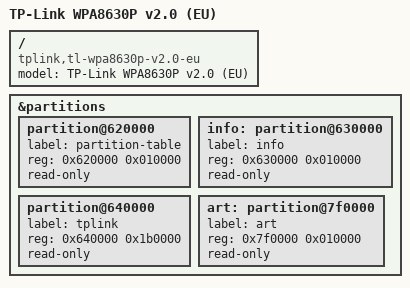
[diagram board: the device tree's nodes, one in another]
// SPDX-License-Identifier: GPL-2.0-or-later OR MIT

#include "qca9563_tplink_tl-wpa8630p-v2.dtsi"

/ {
	compatible = "tplink,tl-wpa8630p-v2.0-eu", "qca,qca9563";
	model = "TP-Link WPA8630P v2.0 (EU)";
};

&partitions {
	partition@620000 {
		label = "partition-table";
		reg = <0x620000 0x010000>;
		read-only;
	};

	info: partition@630000 {
		label = "info";
		reg = <0x630000 0x010000>;
		read-only;
	};

	partition@640000 {
		label = "tplink";
		reg = <0x640000 0x1b0000>;
		read-only;
	};

	art: partition@7f0000 {
		label = "art";
		reg = <0x7f0000 0x010000>;
		read-only;
	};
};
